# STM32H7x7_CM7 register map
File version: 1.0
CPU: CM7 r0p1, little endian, MPU, FPU, 4 interrupt priority bits
Registers are 32-bit, read-write, reset 0x0 unless marked. A register's access mark holds for its fields unless they carry their own. Offsets are from the block's base; [hi:lo] are bit positions; {n}, {i} and the like mark numbered series.

## TIM6 — Basic timers
Base 0x40001000
Same registers: TIM7 0x40001400
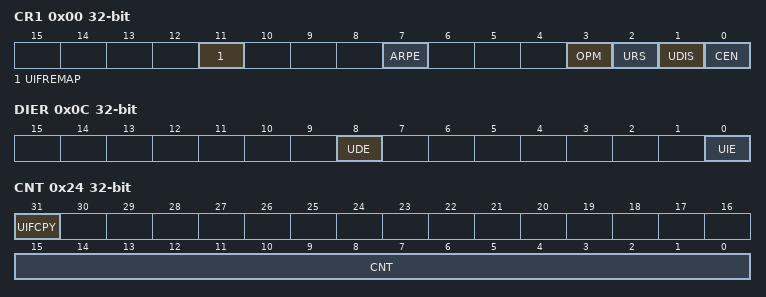
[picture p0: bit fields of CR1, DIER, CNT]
0x00 CR1 — control register 1
  [11] UIFREMAP — UIF status bit remapping
  [7] ARPE — Auto-reload preload enable
  [3] OPM — One-pulse mode
  [2] URS — Update request source
  [1] UDIS — Update disable
  [0] CEN — Counter enable
0x04 CR2 — control register 2
  [6:4] MMS — Master mode selection
0x0C DIER — DMA/Interrupt enable register
  [8] UDE — Update DMA request enable
  [0] UIE — Update interrupt enable
0x10 SR — status register
  [0] UIF — Update interrupt flag
0x14 EGR wo — event generation register
  [0] UG — Update generation
0x24 CNT — counter
  [31] UIFCPY — UIF Copy
  [15:0] CNT — Low counter value
0x28 PSC — prescaler
  [15:0] PSC — Prescaler value
0x2C ARR reset 0xFFFF — auto-reload register
  [15:0] ARR — Low Auto-reload value

## HRTIM_Master — High Resolution Timer: Master Timers
Base 0x40017400
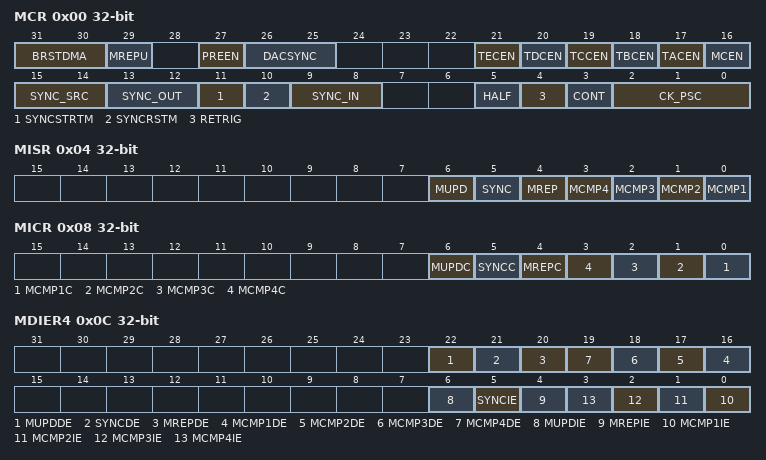
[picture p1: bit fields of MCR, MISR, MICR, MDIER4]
0x00 MCR — Master Timer Control Register
  [31:30] BRSTDMA — Burst DMA Update
  [29] MREPU — Master Timer Repetition update
  [27] PREEN — Preload enable
  [26:25] DACSYNC — AC Synchronization
  [21] TECEN — Timer E counter enable
  [20] TDCEN — Timer D counter enable
  [19] TCCEN — Timer C counter enable
  [18] TBCEN — Timer B counter enable
  [17] TACEN — Timer A counter enable
  [16] MCEN — Master Counter enable
  [15:14] SYNC_SRC — Synchronization source
  [13:12] SYNC_OUT — Synchronization output
  [11] SYNCSTRTM — Synchronization Starts Master
  [10] SYNCRSTM — Synchronization Resets Master
  [9:8] SYNC_IN — ynchronization input
  [5] HALF — Half mode enable
  [4] RETRIG — Master Re-triggerable mode
  [3] CONT — Master Continuous mode
  [2:0] CK_PSC — HRTIM Master Clock prescaler
0x04 MISR ro — Master Timer Interrupt Status Register
  [6] MUPD — Master Update Interrupt Flag
  [5] SYNC — Sync Input Interrupt Flag
  [4] MREP — Master Repetition Interrupt Flag
  [n-1] MCMP{n} (n=1..4) — Master Compare {n} Interrupt Flag
0x08 MICR wo — Master Timer Interrupt Clear Register
  [6] MUPDC — Master update Interrupt flag clear
  [5] SYNCC — Sync Input Interrupt flag clear
  [4] MREPC — Repetition Interrupt flag clear
  [n-1] MCMP{n}C (n=1..4) — Master Compare {n} Interrupt flag clear
0x0C MDIER4
  [22] MUPDDE, [21] SYNCDE, [20] MREPDE, [n+15] MCMP{n}DE (n=1..4), [6] MUPDIE, [5] SYNCIE, [4] MREPIE, [n-1] MCMP{n}IE (n=1..4)
0x10 MCNTR — Master Timer Counter Register
  [15:0] MCNT — Counter value
0x14 MPER reset 0xFFFF — Master Timer Period Register
  [15:0] MPER — Master Timer Period value
0x18 MREP — Master Timer Repetition Register
  [7:0] MREP — Master Timer Repetition counter value
0x1C MCMP1R — Master Timer Compare 1 Register
  [15:0] MCMP1 — Master Timer Compare 1 value
{0x1C+4i} MCMP{i}R (i=2..4) — Master Timer Compare {i} Register
  [15:0] MCMP{i} — Master Timer Compare {i} value

## HASH — Hash processor
Base 0x48021400
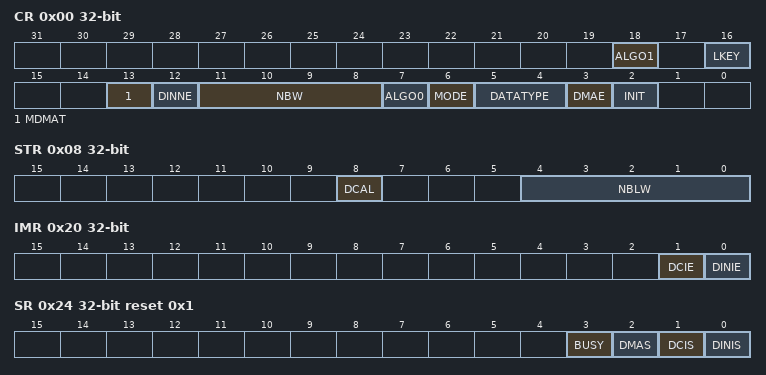
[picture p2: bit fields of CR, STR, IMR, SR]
0x00 CR access per field — control register
  [18] ALGO1 rw — ALGO
  [16] LKEY rw — Long key selection
  [13] MDMAT rw — Multiple DMA Transfers
  [12] DINNE ro — DIN not empty
  [11:8] NBW ro — Number of words already pushed
  [7] ALGO0 rw — Algorithm selection
  [6] MODE rw — Mode selection
  [5:4] DATATYPE rw — Data type selection
  [3] DMAE rw — DMA enable
  [2] INIT wo — Initialize message digest calculation
0x04 DIN — data input register
  [31:0] DATAIN — Data input
0x08 STR access per field — start register
  [8] DCAL wo — Digest calculation
  [4:0] NBLW rw — Number of valid bits in the last word of the message
{0xC+4i} HR{i} ro (i=0..4) — digest registers
  [31:0] H{i}
0x20 IMR — interrupt enable register
  [1] DCIE — Digest calculation completion interrupt enable
  [0] DINIE — Data input interrupt enable
0x24 SR access per field reset 0x1 — status register
  [3] BUSY ro — Busy bit
  [2] DMAS ro — DMA Status
  [1] DCIS rw — Digest calculation completion interrupt status
  [0] DINIS rw — Data input interrupt status
{0xF8+4i} CSR{i} (i=0..53) — context swap registers
0x310 HASH_HR0 ro — HASH digest register
  [31:0] H0
{0x310+4i} HASH_HR{i} ro (i=1..7) — read-only
  [31:0] H{i}
